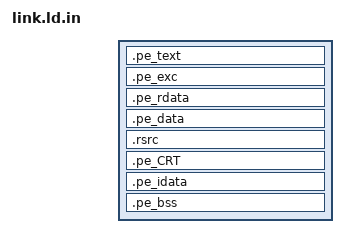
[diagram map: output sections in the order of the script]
SECTIONS {
    /DISCARD/ : { *(.pe_text) }
    .pe_text pe_text_addr : { *(.patch_pe_text) }

    .pe_exc pe_exc_addr : { *(.pe_exc) }
    .pe_rdata pe_rdata_addr : { *(.pe_rdata) }
    .pe_data pe_data_addr : { *(.pe_data) }
    .rsrc pe_rsrc_addr : { *(.pe_rsrc) }
    .pe_CRT pe_CRT_addr : { *(.pe_CRT) }
    .pe_idata pe_idata_addr : { *(.pe_idata) }
    .pe_bss pe_bss_addr : { *(.pe_bss) }
    /DISCARD/ : { *(.pe_edata) *(.pe_reloc) }

    /* The information in this section will be inaccurate */
    /DISCARD/ : { *(.note.gnu.property) }

    . = ALIGN(CONSTANT (MAXPAGESIZE));
}
INSERT BEFORE @INSERT@;
